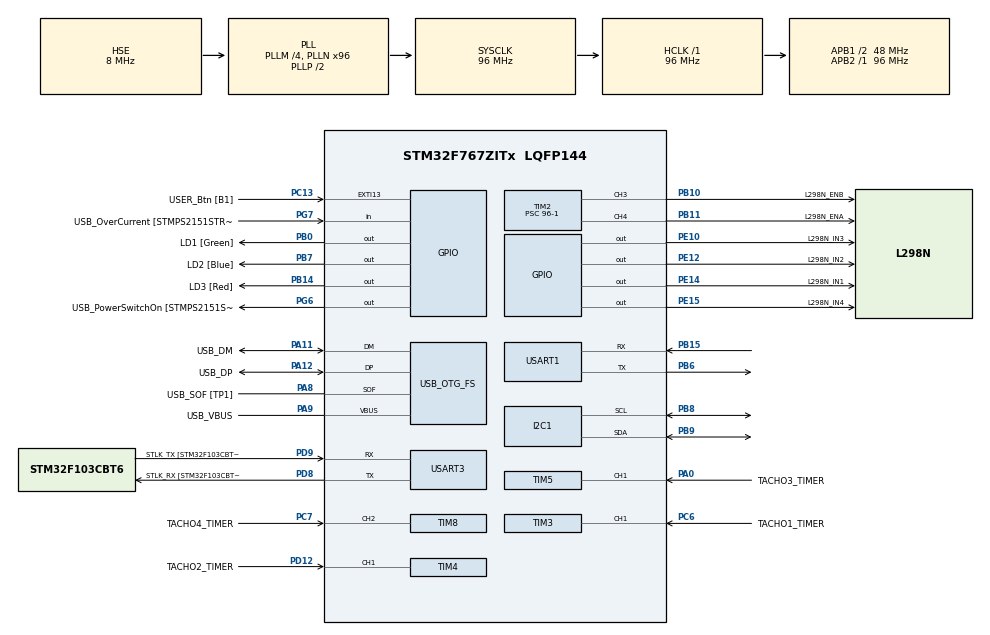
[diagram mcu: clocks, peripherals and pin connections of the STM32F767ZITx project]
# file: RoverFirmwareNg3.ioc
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FREERTOS.Tasks01=defaultTask,8,128,DefaultTaskMain,Default,NULL,Dynamic,NULL,NULL
FREERTOS.configENABLE_FPU=1
FREERTOS.configUSE_NEWLIB_REENTRANT=1
I2C1.Timing=0x20303E5D
Mcu.Family=STM32F7
Mcu.Name=STM32F767ZITx
Mcu.Package=LQFP144
NVIC.PriorityGroup=NVIC_PRIORITYGROUP_4
NVIC.TIM7_IRQn=true\:15\:0\:false\:false\:true\:false\:false\:true\:true
NVIC.TimeBase=TIM7_IRQn
NVIC.TimeBaseIP=TIM7
NVIC.USART1_IRQn=true\:5\:0\:false\:false\:true\:true\:true\:true\:true
NVIC.USART3_IRQn=true\:5\:0\:false\:false\:true\:true\:true\:true\:true
PA0/WKUP.GPIO_Label=TACHO3_TIMER
PA0/WKUP.Signal=S_TIM5_CH1
PA1.GPIO_Label=RMII_REF_CLK [LAN8742A-CZ-TR_REFCLK0]
PA1.Signal=ETH_REF_CLK
PA10.GPIO_Label=USB_ID
PA10.Signal=USB_OTG_FS_ID
PA11.GPIO_Label=USB_DM
PA11.Mode=Device_Only
PA11.Signal=USB_OTG_FS_DM
PA12.GPIO_Label=USB_DP
PA12.Mode=Device_Only
PA12.Signal=USB_OTG_FS_DP
PA13.GPIO_Label=TMS
PA13.Mode=Trace_Asynchronous_SW
PA13.Signal=SYS_JTMS-SWDIO
PA14.GPIO_Label=TCK
PA14.Mode=Trace_Asynchronous_SW
PA14.Signal=SYS_JTCK-SWCLK
PA2.GPIO_Label=RMII_MDIO [LAN8742A-CZ-TR_MDIO]
PA2.Signal=ETH_MDIO
PA7.GPIO_Label=RMII_CRS_DV [LAN8742A-CZ-TR_CRS_DV]
PA7.Signal=ETH_CRS_DV
PA8.GPIO_Label=USB_SOF [TP1]
PA8.Mode=Activate_SOF_FS
PA8.Signal=USB_OTG_FS_SOF
PA9.GPIO_Label=USB_VBUS
PA9.Mode=Activate_VBUS
PA9.Signal=USB_OTG_FS_VBUS
PB0.GPIO_Label=LD1 [Green]
PB0.Signal=GPIO_Output
PB10.GPIO_Label=L298N_ENB
PB10.Signal=S_TIM2_CH3
PB11.GPIO_Label=L298N_ENA
PB11.Signal=S_TIM2_CH4
PB13.GPIO_Label=RMII_TXD1 [LAN8742A-CZ-TR_TXD1]
PB13.Signal=ETH_TXD1
PB14.GPIO_Label=LD3 [Red]
PB14.Signal=GPIO_Output
PB15.Mode=Asynchronous
PB15.Signal=USART1_RX
PB3.GPIO_Label=SWO
PB3.Mode=Trace_Asynchronous_SW
PB3.Signal=SYS_JTDO-SWO
PB6.Mode=Asynchronous
PB6.Signal=USART1_TX
PB7.GPIO_Label=LD2 [Blue]
PB7.Signal=GPIO_Output
PB8.Mode=I2C
PB8.Signal=I2C1_SCL
PB9.Mode=I2C
PB9.Signal=I2C1_SDA
PC1.GPIO_Label=RMII_MDC [LAN8742A-CZ-TR_MDC]
PC1.Signal=ETH_MDC
PC13.GPIO_Label=USER_Btn [B1]
PC13.Signal=GPXTI13
PC14/OSC32_IN.Mode=LSE-External-Oscillator
PC14/OSC32_IN.Signal=RCC_OSC32_IN
PC15/OSC32_OUT.Mode=LSE-External-Oscillator
PC15/OSC32_OUT.Signal=RCC_OSC32_OUT
PC4.GPIO_Label=RMII_RXD0 [LAN8742A-CZ-TR_RXD0]
PC4.Signal=ETH_RXD0
PC5.GPIO_Label=RMII_RXD1 [LAN8742A-CZ-TR_RXD1]
PC5.Signal=ETH_RXD1
PC6.GPIO_Label=TACHO1_TIMER
PC6.GPIO_PuPd=GPIO_NOPULL
PC6.Signal=S_TIM3_CH1
PC7.GPIO_Label=TACHO4_TIMER
PC7.Signal=S_TIM8_CH2
PD12.GPIO_Label=TACHO2_TIMER
PD12.Signal=S_TIM4_CH1
PD8.GPIO_Label=STLK_RX [STM32F103CBT6_PA3]
PD8.Mode=Asynchronous
PD8.Signal=USART3_TX
PD9.GPIO_Label=STLK_TX [STM32F103CBT6_PA2]
PD9.Mode=Asynchronous
PD9.Signal=USART3_RX
PE10.GPIO_Label=L298N_IN3
PE10.Signal=GPIO_Output
PE12.GPIO_Label=L298N_IN2
PE12.Signal=GPIO_Output
PE14.GPIO_Label=L298N_IN1
PE14.Signal=GPIO_Output
PE15.GPIO_Label=L298N_IN4
PE15.Signal=GPIO_Output
PG11.GPIO_Label=RMII_TX_EN [LAN8742A-CZ-TR_TXEN]
PG11.Signal=ETH_TX_EN
PG13.GPIO_Label=RMII_TXD0 [LAN8742A-CZ-TR_TXD0]
PG13.Signal=ETH_TXD0
PG6.GPIO_Label=USB_PowerSwitchOn [STMPS2151STR_EN]
PG6.Signal=GPIO_Output
PG7.GPIO_Label=USB_OverCurrent [STMPS2151STR_FAULT]
PG7.Signal=GPIO_Input
PH0/OSC_IN.GPIO_Label=MCO [STM32F103CBT6_PA8]
PH0/OSC_IN.Mode=HSE-External-Oscillator
PH0/OSC_IN.Signal=RCC_OSC_IN
PH1/OSC_OUT.Mode=HSE-External-Oscillator
PH1/OSC_OUT.Signal=RCC_OSC_OUT
ProjectManager.HeapSize=0x200
ProjectManager.StackSize=0x400
ProjectManager.TargetToolchain=STM32CubeIDE
RCC.48MHZClocksFreq_Value=24000000
RCC.AHBFreq_Value=96000000
RCC.APB1CLKDivider=RCC_HCLK_DIV2
RCC.APB1Freq_Value=48000000
RCC.APB1TimFreq_Value=96000000
RCC.APB2Freq_Value=96000000
RCC.APB2TimFreq_Value=96000000
RCC.CortexFreq_Value=96000000
RCC.HCLKFreq_Value=96000000
RCC.HSE_VALUE=8000000
RCC.HSI_VALUE=16000000
RCC.PLLM=4
RCC.PLLMUL=RCC_PLL_MUL9
RCC.PLLN=96
RCC.PLLQ=4
RCC.PRESCALERUSB=RCC_USBCLKSOURCE_PLL_DIV1_5
RCC.SYSCLKFreq_VALUE=96000000
RCC.SYSCLKSource=RCC_SYSCLKSOURCE_PLLCLK
RCC.SYSCLKSourceVirtual=RCC_SYSCLKSOURCE_PLLCLK
RCC.USBFreq_Value=48000000
RCC.VCOOutputFreq_Value=192000000
SH.S_TIM2_CH3.0=TIM2_CH3,PWM Generation3 CH3
SH.S_TIM2_CH4.0=TIM2_CH4,PWM Generation4 CH4
SH.S_TIM3_CH1.0=TIM3_CH1,TriggerSource_TI1FP1
SH.S_TIM4_CH1.0=TIM4_CH1,TriggerSource_TI1FP1
SH.S_TIM5_CH1.0=TIM5_CH1,TriggerSource_TI1FP1
SH.S_TIM8_CH2.0=TIM8_CH2,TriggerSource_TI2FP2
TIM2.Channel-PWM\ Generation3\ CH3=TIM_CHANNEL_3
TIM2.Channel-PWM\ Generation4\ CH4=TIM_CHANNEL_4
TIM2.Period=1000
TIM2.Prescaler=96-1
TIM2.Pulse-PWM\ Generation3\ CH3=250
TIM2.Pulse-PWM\ Generation4\ CH4=250
TIM3.AutoReloadPreload=TIM_AUTORELOAD_PRELOAD_ENABLE
TIM4.AutoReloadPreload=TIM_AUTORELOAD_PRELOAD_ENABLE
TIM8.AutoReloadPreload=TIM_AUTORELOAD_PRELOAD_ENABLE
USART1.VirtualMode-Asynchronous=VM_ASYNC
USART3.VirtualMode-Asynchronous=VM_ASYNC
USB_OTG_FS.VirtualMode=Device_Only
VP_FREERTOS_VS_CMSIS_V2.Mode=CMSIS_V2
VP_SYS_VS_tim7.Mode=TIM7
VP_TIM3_VS_ControllerModeClock.Mode=Clock Mode
VP_TIM4_VS_ControllerModeClock.Mode=Clock Mode
VP_TIM5_VS_ControllerModeClock.Mode=Clock Mode
VP_TIM8_VS_ControllerModeClock.Mode=Clock Mode
board=NUCLEO-F767ZI

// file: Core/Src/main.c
/* USER CODE BEGIN Header */
/**
  ******************************************************************************
  * @file           : main.c
  * @brief          : Main program body
  ******************************************************************************
  * @attention
  *
  * Copyright (c) 2023 STMicroelectronics.
  * All rights reserved.
  *
  * This software is licensed under terms that can be found in the LICENSE file
  * in the root directory of this software component.
  * If no LICENSE file comes with this software, it is provided AS-IS.
  *
  ******************************************************************************
  */
/* USER CODE END Header */
#include "main.h"
#include "cmsis_os.h"
#include "i2c.h"
#include "tim.h"
#include "usart.h"
#include "usb_otg.h"
#include "gpio.h"

/* USER CODE BEGIN Includes */
#include "ApplicationConfig.h"
extern void ApplicationSetup(const ApplicationConfig* Config);
/* USER CODE END Includes */

void SystemClock_Config(void);
void MX_FREERTOS_Init(void);

int main(void)
{
  /* USER CODE BEGIN 1 */
	//printf("Application started\r\n");
  /* USER CODE END 1 */

  /* MCU Configuration--------------------------------------------------------*/

  /* Reset of all peripherals, Initializes the Flash interface and the Systick. */
  HAL_Init();

  /* USER CODE BEGIN Init */
  //HAL_NVIC_SetPriority(USART3_IRQn, 0, 0);
  //HAL_NVIC_EnableIRQ(USART3_IRQn);
  /* USER CODE END Init */

  /* Configure the system clock */
  SystemClock_Config();

  /* Initialize all configured peripherals */
  MX_GPIO_Init();
  MX_USB_OTG_FS_PCD_Init();
  MX_TIM2_Init();
  MX_USART1_UART_Init();
  MX_I2C1_Init();
  MX_USART3_UART_Init();
  MX_TIM3_Init();
  MX_TIM4_Init();
  MX_TIM5_Init();
  MX_TIM8_Init();
  /* USER CODE BEGIN 2 */
  ApplicationConfig Config;
  //Config.UartTcTmHandle = &huart3; // Development mode (USB)
  Config.UartTcTmHandle = &huart1; // Production mode (Rx/Tx pins)
  Config.PwmTimerHandle = &htim2;
  Config.TachoTimerHandlers[0] = &htim3;
  Config.TachoTimerHandlers[1] = &htim4;
  Config.TachoTimerHandlers[2] = &htim5;
  Config.TachoTimerHandlers[3] = &htim8;

  ApplicationSetup(&Config);
  /* USER CODE END 2 */

  /* Init scheduler */
  osKernelInitialize();  /* Call init function for freertos objects (in freertos.c) */
  MX_FREERTOS_Init();

  /* Start scheduler */
  osKernelStart();

  /* We should never get here as control is now taken by the scheduler */
  /* Infinite loop */
  while (1)
  {

  }
}

void SystemClock_Config(void)
{
  RCC_OscInitTypeDef RCC_OscInitStruct = {0};
  RCC_ClkInitTypeDef RCC_ClkInitStruct = {0};

  /** Configure LSE Drive Capability
  */
  HAL_PWR_EnableBkUpAccess();

  /** Configure the main internal regulator output voltage
  */
  __HAL_RCC_PWR_CLK_ENABLE();
  __HAL_PWR_VOLTAGESCALING_CONFIG(PWR_REGULATOR_VOLTAGE_SCALE3);

  /** Initializes the RCC Oscillators according to the specified parameters
  * in the RCC_OscInitTypeDef structure.
  */
  RCC_OscInitStruct.OscillatorType = RCC_OSCILLATORTYPE_HSE;
  RCC_OscInitStruct.HSEState = RCC_HSE_ON;
  RCC_OscInitStruct.PLL.PLLState = RCC_PLL_ON;
  RCC_OscInitStruct.PLL.PLLSource = RCC_PLLSOURCE_HSE;
  RCC_OscInitStruct.PLL.PLLM = 4;
  RCC_OscInitStruct.PLL.PLLN = 96;
  RCC_OscInitStruct.PLL.PLLP = RCC_PLLP_DIV2;
  RCC_OscInitStruct.PLL.PLLQ = 4;
  RCC_OscInitStruct.PLL.PLLR = 2;
  if (HAL_RCC_OscConfig(&RCC_OscInitStruct) != HAL_OK)
  {
    Error_Handler();
  }

  /** Activate the Over-Drive mode
  */
  if (HAL_PWREx_EnableOverDrive() != HAL_OK)
  {
    Error_Handler();
  }

  /** Initializes the CPU, AHB and APB buses clocks
  */
  RCC_ClkInitStruct.ClockType = RCC_CLOCKTYPE_HCLK|RCC_CLOCKTYPE_SYSCLK
                              |RCC_CLOCKTYPE_PCLK1|RCC_CLOCKTYPE_PCLK2;
  RCC_ClkInitStruct.SYSCLKSource = RCC_SYSCLKSOURCE_PLLCLK;
  RCC_ClkInitStruct.AHBCLKDivider = RCC_SYSCLK_DIV1;
  RCC_ClkInitStruct.APB1CLKDivider = RCC_HCLK_DIV2;
  RCC_ClkInitStruct.APB2CLKDivider = RCC_HCLK_DIV1;

  if (HAL_RCC_ClockConfig(&RCC_ClkInitStruct, FLASH_LATENCY_3) != HAL_OK)
  {
    Error_Handler();
  }
}

void HAL_TIM_PeriodElapsedCallback(TIM_HandleTypeDef *htim)
{
  if (htim->Instance == TIM7) {
    HAL_IncTick();
  }
}

void Error_Handler(void)
{
  __disable_irq();
  while (1)
  {
  }
}

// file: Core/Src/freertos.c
/* USER CODE BEGIN Header */
/**
  ******************************************************************************
  * File Name          : freertos.c
  * Description        : Code for freertos applications
  ******************************************************************************
  * @attention
  *
  * Copyright (c) 2023 STMicroelectronics.
  * All rights reserved.
  *
  * This software is licensed under terms that can be found in the LICENSE file
  * in the root directory of this software component.
  * If no LICENSE file comes with this software, it is provided AS-IS.
  *
  ******************************************************************************
  */
/* USER CODE END Header */

#include "FreeRTOS.h"
#include "task.h"
#include "main.h"
#include "cmsis_os.h"

/* Definitions for defaultTask */
osThreadId_t defaultTaskHandle;
const osThreadAttr_t defaultTask_attributes = {
  .name = "defaultTask",
  .stack_size = 128 * 4,
  .priority = (osPriority_t) osPriorityLow,
};

void DefaultTaskMain(void *argument);

void MX_FREERTOS_Init(void); /* (MISRA C 2004 rule 8.1) */

void MX_FREERTOS_Init(void) {

  /* Create the thread(s) */
  /* creation of defaultTask */
  defaultTaskHandle = osThreadNew(DefaultTaskMain, NULL, &defaultTask_attributes);

}

void DefaultTaskMain(void *argument)
{
  /* USER CODE BEGIN DefaultTaskMain */
	for(;;)
	{
		//printf("I'm alive!!!\r\n");
		osDelay(1000);
	}
  /* USER CODE END DefaultTaskMain */
}
